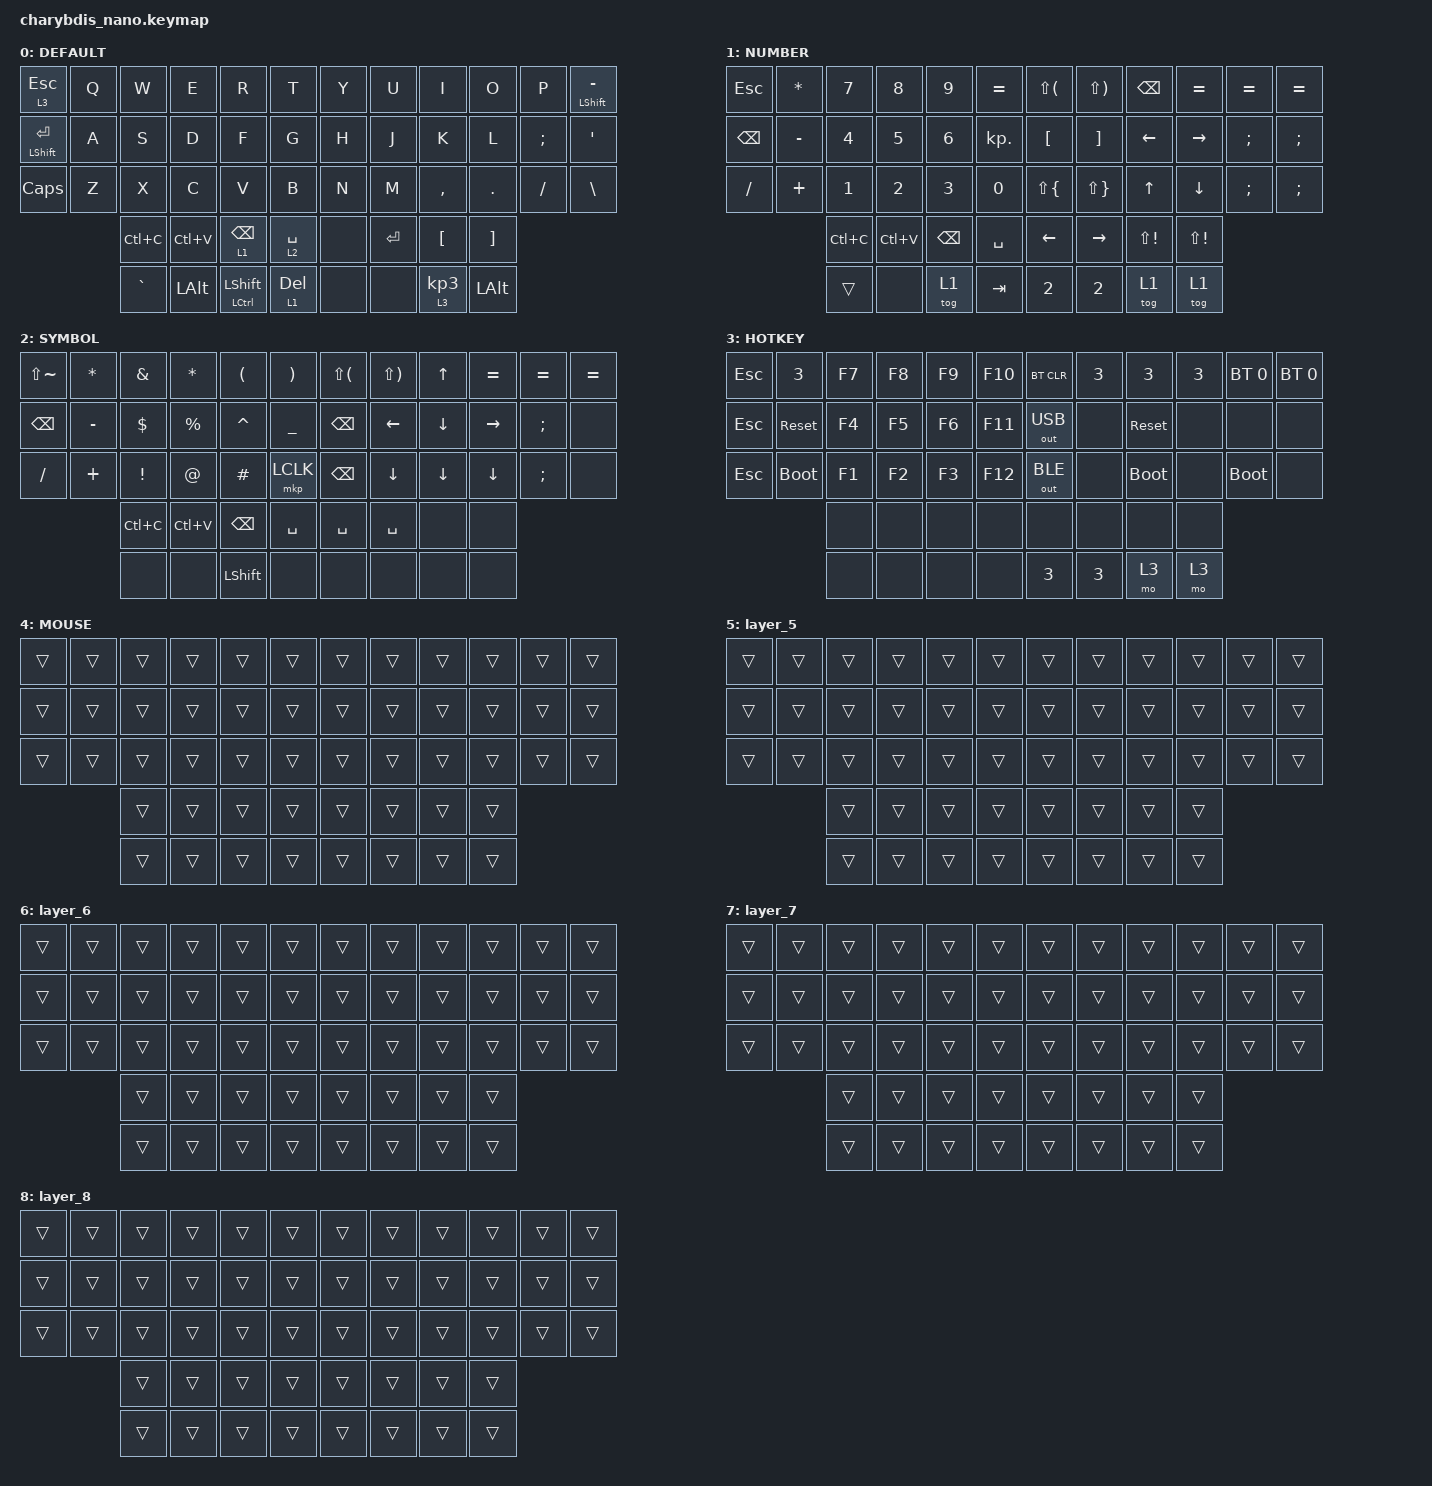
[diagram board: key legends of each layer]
#include <behaviors/mouse_keys.dtsi>
#include <dt-bindings/zmk/mouse.h>
#include <dt-bindings/zmk/runtime_input_processor.h>
#include <dt-bindings/input/input-event-codes.h>
#include <behaviors/runtime-input-processor.dtsi>
#include <behaviors.dtsi>
#include <dt-bindings/zmk/bt.h>
#include <dt-bindings/zmk/keys.h>
#include <dt-bindings/zmk/outputs.h>
#include <dt-bindings/zmk/pointing.h>

#define DEFAULT 0
#define NUMBER  1
#define SYMBOL  2
#define HOTKEY  3
#define MOUSE   4

&lt {
    tapping-term-ms = <240>;
    flavor = "balanced";
    quick-tap-ms = <150>;
};

&mt {
    tapping-term-ms = <200>;
    flavor = "tap-preferred";
    quick-tap-ms = <150>;
};

/ {
    behaviors {
        td0: tap_dance_0 {
            compatible = "zmk,behavior-tap-dance";
            label = "L_CLK";
            #binding-cells = <0>;
            tapping-term-ms = <200>;
            bindings = <&mkp LCLK>, <&mkp LCLK>;
        };

        td1: tap_dance_1 {
            compatible = "zmk,behavior-tap-dance";
            label = "M_CLK";
            #binding-cells = <0>;
            tapping-term-ms = <200>;
            bindings = <&mkp MCLK>, <&mkp MCLK>;
        };

        td2: tap_dance_2 {
            compatible = "zmk,behavior-tap-dance";
            label = "R_CLK";
            #binding-cells = <0>;
            tapping-term-ms = <200>;
            bindings = <&mkp RCLK>, <&mkp RCLK>;
        };
    };

    combos {
        compatible = "zmk,combos";

        combo_left {
            timeout-ms = <50>;
            key-positions = <>;
            bindings = <&mkp LCLK>;
        };

        combo_LSHFT {
            timeout-ms = <50>;
            key-positions = <>;
            bindings = <&mkp RCLK>;
        };

        combo_LSH {
            timeout-ms = <50>;
            key-positions = <14 15>;
            bindings = <&kp LSHFT>;
        };

        combo_LGUI {
            timeout-ms = <50>;
            key-positions = <>;
            bindings = <&kp LGUI>;
        };

        combo_GU {
            timeout-ms = <50>;
            key-positions = <>;
            bindings = <&tog 1>;
        };
    };

    keymap {
        compatible = "zmk,keymap";

        default_layer {
            label = "DEFAULT";
            bindings = <
&lt 3 ESC             &kp Q  &kp W      &kp E      &kp R            &kp T        &kp Y  &kp U      &kp I              &kp O     &kp P     &mt LEFT_SHIFT MINUS
&mt LEFT_SHIFT ENTER  &kp A  &kp S      &kp D      &kp F            &kp G        &kp H  &kp J      &kp K              &kp L     &kp SEMI  &kp SQT
&kp CAPS              &kp Z  &kp X      &kp C      &kp V            &kp B        &kp N  &kp M      &kp COMMA          &kp DOT   &kp FSLH  &kp BSLH
                             &kp LC(C)  &kp LC(V)  &lt 1 BSPC       &lt 2 SPACE  &none  &kp ENTER  &kp LBKT           &kp RBKT
                             &kp GRAVE  &kp LALT   &mt LCTRL LSHFT  &lt 1 DEL    &none  &none      &lt 3 KP_NUMBER_3  &kp LALT
            >;
        };

        number_layer {
            label = "NUMBER";
            bindings = <
&kp ESC   &kp STAR   &kp N7     &kp N8     &kp N9    &kp EQUAL   &kp LS(LPAR)  &kp LS(RPAR)  &kp BSPC      &kp EQUAL     &kp EQUAL  &kp EQUAL
&kp BSPC  &kp MINUS  &kp N4     &kp N5     &kp N6    &kp KP_DOT  &kp LBKT      &kp RBKT      &kp LEFT      &kp RIGHT     &kp SEMI   &kp SEMI
&kp FSLH  &kp PLUS   &kp N1     &kp N2     &kp N3    &kp N0      &kp LS(LBRC)  &kp LS(RBRC)  &kp UP        &kp DOWN      &kp SEMI   &kp SEMI
                     &kp LC(C)  &kp LC(V)  &kp BSPC  &kp SPACE   &kp LEFT      &kp RIGHT     &kp LS(EXCL)  &kp LS(EXCL)
                     &trans     &none      &tog 1    &kp TAB     &kp N2        &kp N2        &tog 1        &tog 1
            >;
        };

        symbol_layer {
            label = "SYMBOL";
            bindings = <
&kp LS(TILDE)  &kp STAR   &kp AMPS   &kp STAR   &kp LPAR   &kp RPAR   &kp LS(LPAR)  &kp LS(RPAR)  &kp UP    &kp EQUAL  &kp EQUAL  &kp EQUAL
&kp BSPC       &kp MINUS  &kp DLLR   &kp PRCNT  &kp CARET  &kp UNDER  &kp BSPC      &kp LEFT      &kp DOWN  &kp RIGHT  &kp SEMI   &none
&kp FSLH       &kp PLUS   &kp EXCL   &kp AT     &kp HASH   &mkp LCLK  &kp BSPC      &kp DOWN      &kp DOWN  &kp DOWN   &kp SEMI   &none
                          &kp LC(C)  &kp LC(V)  &kp BSPC   &kp SPACE  &kp SPACE     &kp SPACE     &none     &none
                          &none      &none      &kp LSHFT  &none      &none         &none         &none     &none
            >;
        };

        hotkey_layer {
            label = "HOTKEY";
            bindings = <
&kp ESC  &kp N3       &kp F7  &kp F8  &kp F9  &kp F10  &bt BT_CLR    &kp N3        &kp N3       &kp N3  &bt BT_SEL 0  &bt BT_SEL 0
&kp ESC  &sys_reset   &kp F4  &kp F5  &kp F6  &kp F11  &out OUT_USB  &none         &sys_reset   &none   &none         &none
&kp ESC  &bootloader  &kp F1  &kp F2  &kp F3  &kp F12  &out OUT_BLE  &none         &bootloader  &none   &bootloader   &none
                      &none   &none   &none   &none    &none         &none         &none        &none
                      &none   &none   &none   &none    &kp NUMBER_3  &kp NUMBER_3  &mo 3        &mo 3
            >;
        };

        mouse_layer {
            label = "MOUSE";
            bindings = <
&trans  &trans  &trans  &trans  &trans  &trans  &trans  &trans  &trans  &trans  &trans  &trans
&trans  &trans  &trans  &trans  &trans  &trans  &trans  &trans  &trans  &trans  &trans  &trans
&trans  &trans  &trans  &trans  &trans  &trans  &trans  &trans  &trans  &trans  &trans  &trans
                &trans  &trans  &trans  &trans  &trans  &trans  &trans  &trans
                &trans  &trans  &trans  &trans  &trans  &trans  &trans  &trans
            >;
        };

        layer_5 {
            bindings = <
&trans  &trans  &trans  &trans  &trans  &trans  &trans  &trans  &trans  &trans  &trans  &trans
&trans  &trans  &trans  &trans  &trans  &trans  &trans  &trans  &trans  &trans  &trans  &trans
&trans  &trans  &trans  &trans  &trans  &trans  &trans  &trans  &trans  &trans  &trans  &trans
                &trans  &trans  &trans  &trans  &trans  &trans  &trans  &trans
                &trans  &trans  &trans  &trans  &trans  &trans  &trans  &trans
            >;
        };

        layer_6 {
            bindings = <
&trans  &trans  &trans  &trans  &trans  &trans  &trans  &trans  &trans  &trans  &trans  &trans
&trans  &trans  &trans  &trans  &trans  &trans  &trans  &trans  &trans  &trans  &trans  &trans
&trans  &trans  &trans  &trans  &trans  &trans  &trans  &trans  &trans  &trans  &trans  &trans
                &trans  &trans  &trans  &trans  &trans  &trans  &trans  &trans
                &trans  &trans  &trans  &trans  &trans  &trans  &trans  &trans
            >;
        };

        layer_7 {
            bindings = <
&trans  &trans  &trans  &trans  &trans  &trans  &trans  &trans  &trans  &trans  &trans  &trans
&trans  &trans  &trans  &trans  &trans  &trans  &trans  &trans  &trans  &trans  &trans  &trans
&trans  &trans  &trans  &trans  &trans  &trans  &trans  &trans  &trans  &trans  &trans  &trans
                &trans  &trans  &trans  &trans  &trans  &trans  &trans  &trans
                &trans  &trans  &trans  &trans  &trans  &trans  &trans  &trans
            >;
        };

        layer_8 {
            bindings = <
&trans  &trans  &trans  &trans  &trans  &trans  &trans  &trans  &trans  &trans  &trans  &trans
&trans  &trans  &trans  &trans  &trans  &trans  &trans  &trans  &trans  &trans  &trans  &trans
&trans  &trans  &trans  &trans  &trans  &trans  &trans  &trans  &trans  &trans  &trans  &trans
                &trans  &trans  &trans  &trans  &trans  &trans  &trans  &trans
                &trans  &trans  &trans  &trans  &trans  &trans  &trans  &trans
            >;
        };
    };
};

&mouse_runtime_input_processor {
    temp-layer-enabled;
    temp-layer = <4>;
    temp-layer-activation-delay-ms = <200>;
    temp-layer-deactivation-delay-ms = <400>;
};

&scroll_runtime_input_processor {
    active-layers = <BIT(1)>;
    x-codes = <INPUT_REL_X>;
    y-codes = <INPUT_REL_Y>;
    xy-to-scroll-enabled;
    axis-snap-threshold = <100>;
};
